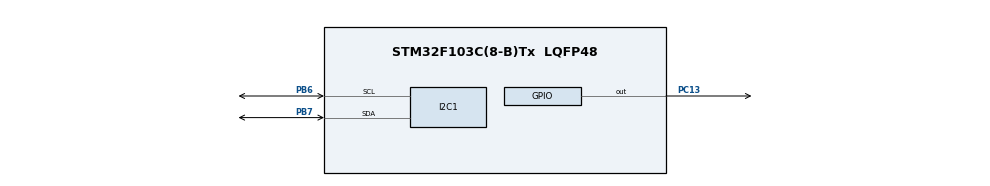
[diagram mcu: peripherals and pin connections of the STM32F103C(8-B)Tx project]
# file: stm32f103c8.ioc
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Mcu.Family=STM32F1
RCC.APB2Freq_Value=8000000
PA14.Mode=Serial_Wire
PB7.Signal=I2C1_SDA
PC13-TAMPER-RTC.Signal=GPIO_Output
PA13.Mode=Serial_Wire
Mcu.Name=STM32F103C(8-B)Tx
Mcu.Package=LQFP48
ProjectManager.StackSize=0x400
PA13.Signal=SYS_JTMS-SWDIO
PB7.Mode=I2C
PA14.Signal=SYS_JTCK-SWCLK
ProjectManager.HeapSize=0x200
ProjectManager.TargetToolchain=MDK-ARM V5.27
NVIC.PriorityGroup=NVIC_PRIORITYGROUP_4
PB6.Signal=I2C1_SCL
PB6.Mode=I2C
RCC.APB1Freq_Value=8000000
board=custom

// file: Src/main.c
/* USER CODE BEGIN Header */
/**
  ******************************************************************************
  * @file           : main.c
  * @brief          : Main program body
  ******************************************************************************
  * @attention
  *
  * <h2><center>&copy; Copyright (c) 2020 STMicroelectronics.
  * All rights reserved.</center></h2>
  *
  * This software component is licensed by ST under BSD 3-Clause license,
  * the "License"; You may not use this file except in compliance with the
  * License. You may obtain a copy of the License at:
  *                        opensource.org/licenses/BSD-3-Clause
  *
  ******************************************************************************
  */
/* USER CODE END Header */

#include "main.h"

/* USER CODE BEGIN Includes */

// if USE_UG_LIB is defined -- use version ug8
// else use ug82 -- which is not working
#define USE_UG_LIB

#ifdef USE_UG_LIB
#include "u8g_com_arm_stm32.h"
#else
#include "u8g2_com_arm_stm32.h"
#endif
/* USER CODE END Includes */

I2C_HandleTypeDef hi2c1;

void SystemClock_Config(void);
static void MX_GPIO_Init(void);
static void MX_I2C1_Init(void);

int main(void)
{
  /* USER CODE BEGIN 1 */

#ifdef USE_UG_LIB
  u8g_t u8g;
#else
  u8g2_t u8g2;
#endif

  /* USER CODE END 1 */

  /* MCU Configuration--------------------------------------------------------*/

  /* Reset of all peripherals, Initializes the Flash interface and the Systick. */
  HAL_Init();

  /* Configure the system clock */
  SystemClock_Config();

  /* Initialize all configured peripherals */
  MX_GPIO_Init();
  MX_I2C1_Init();
  /* USER CODE BEGIN 2 */

#ifdef USE_UG_LIB
  u8g_InitComFn(&u8g, &u8g_dev_ssd1306_128x32_i2c, u8g_com_arm_stm32_ssd_i2c_fn);
#else
  u8g2_SetI2CAddress(&u8g2, SSD1306_I2C_ADDRESS);

  //Full screen buffer mode
  u8g2_Setup_ssd1306_i2c_128x32_winstar_f(&u8g2, U8G2_R0, u8x8_byte_stm32_hw_i2c, u8x8_stm32_gpio_and_delay);

   // transfer init sequence to the display
  u8g2_InitDisplay(&u8g2);
  // turn off display
  u8g2_SetPowerSave(&u8g2, 1);
  // turn on display
  HAL_Delay(2000);
  u8g2_SetPowerSave(&u8g2, 0);
#endif

  /* USER CODE END 2 */

  /* Infinite loop */
  while (1)
  {

    /* USER CODE BEGIN 3 */

    // BLINKY
    HAL_GPIO_WritePin(GPIOC, GPIO_PIN_13, GPIO_PIN_RESET);
    HAL_Delay(500);

    HAL_GPIO_WritePin(GPIOC, GPIO_PIN_13, GPIO_PIN_SET);
    HAL_Delay(500);

#ifdef USE_UG_LIB
    //draw test
    u8g_FirstPage(&u8g);
    do {
        u8g_SetFont(&u8g, u8g_font_profont12);
        u8g_DrawStr(&u8g, 0, 12,  "  Hello :)");
        u8g_DrawStr(&u8g, 0, 26,  "  STM32F103C8T6 FTW");
    } while (u8g_NextPage(&u8g));

    HAL_Delay(2000);

    u8g_FirstPage(&u8g);
    do {
        u8g_SetFont(&u8g, u8g_font_profont12);
        u8g_DrawStr(&u8g, 0, 15, "tdaileygithub");
        u8g_DrawStr(&u8g, 0, 26, "      .github.io");
    } while (u8g_NextPage(&u8g));

    u8g_FirstPage(&u8g);
    do
    {
      u8g_SetFont(&u8g, u8g_font_profont12);
      u8g_DrawStr(&u8g, 0, 13,  "Hello World");
      u8g_DrawFilledEllipse(&u8g, 105, 15, 8, 8, U8G_DRAW_ALL);
    } while (u8g_NextPage(&u8g));

#else
    u8g2_FirstPage(&u8g2);
    do
    {
      u8g2_SetFont(&u8g2, u8g2_font_ncenB10_tr);
      u8g2_DrawStr(&u8g2, 0, 13,  "Hello World");
      u8g2_DrawFilledEllipse(&u8g2, 105, 15, 8, 8, U8G2_DRAW_ALL);
    } while (u8g2_NextPage(&u8g2));

    u8g2_FirstPage(&u8g2);
    do
    {
      u8g2_SetFont(&u8g2, u8g2_font_ncenB10_tr);
      u8g2_DrawStr(&u8g2, 0, 13,  "Cool");
      u8g2_DrawDisc(&u8g2, 50, 15, 8, U8G2_DRAW_ALL);
    } while (u8g2_NextPage(&u8g2));

#endif

    HAL_Delay(2000);

  }
  /* USER CODE END 3 */
}

void SystemClock_Config(void)
{
  RCC_OscInitTypeDef RCC_OscInitStruct = {0};
  RCC_ClkInitTypeDef RCC_ClkInitStruct = {0};

  /** Initializes the CPU, AHB and APB busses clocks
  */
  RCC_OscInitStruct.OscillatorType = RCC_OSCILLATORTYPE_HSI;
  RCC_OscInitStruct.HSIState = RCC_HSI_ON;
  RCC_OscInitStruct.HSICalibrationValue = RCC_HSICALIBRATION_DEFAULT;
  RCC_OscInitStruct.PLL.PLLState = RCC_PLL_NONE;
  if (HAL_RCC_OscConfig(&RCC_OscInitStruct) != HAL_OK)
  {
    Error_Handler();
  }
  /** Initializes the CPU, AHB and APB busses clocks
  */
  RCC_ClkInitStruct.ClockType = RCC_CLOCKTYPE_HCLK|RCC_CLOCKTYPE_SYSCLK
                              |RCC_CLOCKTYPE_PCLK1|RCC_CLOCKTYPE_PCLK2;
  RCC_ClkInitStruct.SYSCLKSource = RCC_SYSCLKSOURCE_HSI;
  RCC_ClkInitStruct.AHBCLKDivider = RCC_SYSCLK_DIV1;
  RCC_ClkInitStruct.APB1CLKDivider = RCC_HCLK_DIV1;
  RCC_ClkInitStruct.APB2CLKDivider = RCC_HCLK_DIV1;

  if (HAL_RCC_ClockConfig(&RCC_ClkInitStruct, FLASH_LATENCY_0) != HAL_OK)
  {
    Error_Handler();
  }
}

static void MX_I2C1_Init(void)
{

  hi2c1.Instance = I2C1;
  hi2c1.Init.ClockSpeed = 100000;
  hi2c1.Init.DutyCycle = I2C_DUTYCYCLE_2;
  hi2c1.Init.OwnAddress1 = 0;
  hi2c1.Init.AddressingMode = I2C_ADDRESSINGMODE_7BIT;
  hi2c1.Init.DualAddressMode = I2C_DUALADDRESS_DISABLE;
  hi2c1.Init.OwnAddress2 = 0;
  hi2c1.Init.GeneralCallMode = I2C_GENERALCALL_DISABLE;
  hi2c1.Init.NoStretchMode = I2C_NOSTRETCH_DISABLE;
  if (HAL_I2C_Init(&hi2c1) != HAL_OK)
  {
    Error_Handler();
  }

}

static void MX_GPIO_Init(void)
{
  GPIO_InitTypeDef GPIO_InitStruct = {0};

  /* GPIO Ports Clock Enable */
  __HAL_RCC_GPIOC_CLK_ENABLE();
  __HAL_RCC_GPIOA_CLK_ENABLE();
  __HAL_RCC_GPIOB_CLK_ENABLE();

  /*Configure GPIO pin Output Level */
  HAL_GPIO_WritePin(GPIOC, GPIO_PIN_13, GPIO_PIN_RESET);

  /*Configure GPIO pin : PC13 */
  GPIO_InitStruct.Pin = GPIO_PIN_13;
  GPIO_InitStruct.Mode = GPIO_MODE_OUTPUT_PP;
  GPIO_InitStruct.Pull = GPIO_NOPULL;
  GPIO_InitStruct.Speed = GPIO_SPEED_FREQ_LOW;
  HAL_GPIO_Init(GPIOC, &GPIO_InitStruct);

}

void Error_Handler(void)
{
}

/************************ (C) COPYRIGHT STMicroelectronics *****END OF FILE****/
